# AVR32DA48 device description
Architecture: AVR8X; Family: AVR DA
Registers are 8-bit, read-write, reset 0x0 unless marked. A register's access mark holds for its fields unless they carry their own. Offsets are from the block's base; [hi:lo] are bit positions; {n}, {i} and the like mark numbered series; 'fields as' and 'values as' point back to an identical list; <NAME> marks a mode.

## SPI — Serial Peripheral Interface
Instances: SPI0 0x0940, SPI1 0x0960
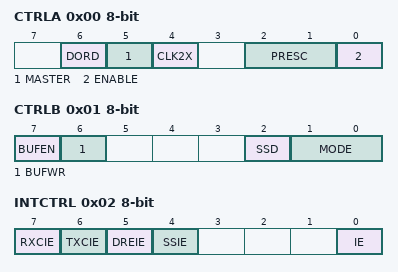
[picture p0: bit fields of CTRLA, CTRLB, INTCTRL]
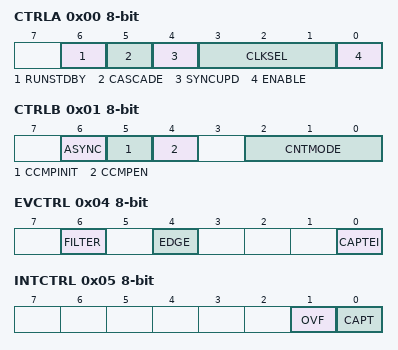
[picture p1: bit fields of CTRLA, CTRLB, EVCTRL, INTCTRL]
0x00 CTRLA — Control A
  [6] DORD — Data Order Setting
  [5] MASTER — Master Operation Enable
  [4] CLK2X — Enable Double Speed
  [2:1] PRESC — Prescaler
    0=DIV4 (System Clock / 4); 1=DIV16 (System Clock / 16); 2=DIV64 (System Clock / 64); 3=DIV128 (System Clock / 128)
  [0] ENABLE — Enable Module
0x01 CTRLB — Control B
  [7] BUFEN — Buffer Mode Enable
  [6] BUFWR — Buffer Mode Wait for Receive
  [2] SSD — Slave Select Disable
  [1:0] MODE — SPI Mode
    {v}=SPI Mode {v} (v=0..3)
0x02 INTCTRL — Interrupt Control
  [7] RXCIE — Receive Complete Interrupt Enable
  [6] TXCIE — Transfer Complete Interrupt Enable
  [5] DREIE — Data Register Empty Interrupt Enable
  [4] SSIE — Slave Select Trigger Interrupt Enable
  [0] IE — Interrupt Enable
0x03 INTFLAGS — Interrupt Flags
  [7] RXCIF <BUFFERED> — Receive Complete Interrupt Flag
  [6] TXCIF <BUFFERED> — Transfer Complete Interrupt Flag
  [5] DREIF <BUFFERED> — Data Register Empty Interrupt Flag
  [4] SSIF <BUFFERED> — Slave Select Trigger Interrupt Flag
  [0] BUFOVF <BUFFERED> — Buffer Overflow
  [7] IF <DEFAULT> — Interrupt Flag
  [6] WRCOL <DEFAULT> — Write Collision
0x04 DATA reset not defined

## SYSCFG — System Configuration Registers
Instances: SYSCFG 0x0F00
0x01 REVID reset not defined — Revision ID
0x18 OCDMCTRL reset not defined — OCD Message Control
0x19 OCDMSTATUS — OCD Message Status
  [0] OCDMR — OCD Message Read

## TCB — 16-bit Timer Type B
Instances: TCB{n} {0xB00+0x10*n} (n=0..3)
0x00 CTRLA — Control A
  [6] RUNSTDBY — Run Standby
  [5] CASCADE — Cascade two timers
  [4] SYNCUPD — Synchronize Update
  [3:1] CLKSEL — Clock Select
    0=DIV1 (CLK_PER); 1=DIV2 (CLK_PER/2); 2=TCA0 (Use CLK_TCA from TCA0); 7=EVENT (Count on event edge); 3=TCA1 (Use CLK_TCA from TCA1)
  [0] ENABLE
0x01 CTRLB — Control Register B
  [6] ASYNC — Asynchronous Enable
  [5] CCMPINIT — Pin Initial State
  [4] CCMPEN — Pin Output Enable
  [2:0] CNTMODE — Timer Mode
    0=INT (Periodic Interrupt); 1=TIMEOUT (Periodic Timeout); 2=CAPT (Input Capture Event); 3=FRQ (Input Capture Frequency measurement); 4=PW (Input Capture Pulse-Width measurement); 5=FRQPW (Input Capture Frequency and Pulse-Width measurement); 6=SINGLE (Single Shot); 7=PWM8 (8-bit PWM)
0x04 EVCTRL — Event Control
  [6] FILTER — Input Capture Noise Cancellation Filter
  [4] EDGE — Event Edge
  [0] CAPTEI — Event Input Enable
0x05 INTCTRL — Interrupt Control
  [1] OVF — Overflow
  [0] CAPT — Capture or Timeout
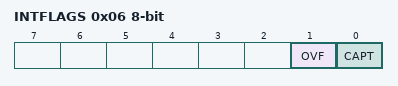
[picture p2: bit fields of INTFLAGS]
0x06 INTFLAGS — Interrupt Flags
  [1] OVF — Overflow
  [0] CAPT — Capture or Timeout
0x07 STATUS ro
  [0] RUN
0x08 DBGCTRL — Debug Control
  [0] DBGRUN — Debug Run
0x09 TEMP reset not defined — Temporary Value
0x0A CNT 16-bit — Count
0x0C CCMP 16-bit reset not defined — Compare or Capture

## TWI — Two-Wire Interface
Instances: TWI0 0x0900, TWI1 0x0920
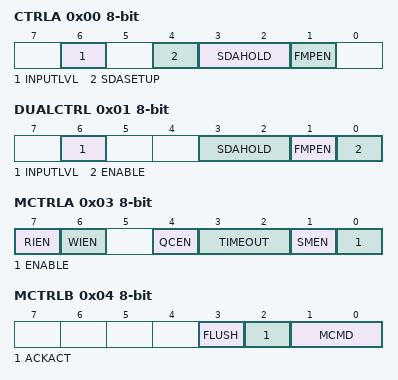
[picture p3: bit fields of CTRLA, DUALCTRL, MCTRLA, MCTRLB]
0x00 CTRLA — Control A
  [6] INPUTLVL <DEFAULT> — Input Voltage Transition Level
    0=I2C (I2C input voltage transition level); 1=SMBUS (SMBus 3.0 input voltage transition level)
  [4] SDASETUP <DEFAULT> — SDA Setup Time
    0=4CYC (SDA setup time is 4 clock cycles); 1=8CYC (SDA setup time is 8 clock cycles)
  [3:2] SDAHOLD <DEFAULT> — SDA Hold Time
    0=OFF (SDA hold time off); 1=50NS (Typical 50ns hold time); 2=300NS (Typical 300ns hold time); 3=500NS (Typical 500ns hold time)
  [1] FMPEN <DEFAULT> — FM Plus Enable
0x01 DUALCTRL — Dual Control
  [6] INPUTLVL <DEFAULT> — Input Voltage Transition Level
    values as CTRLA.INPUTLVL<DEFAULT>
  [3:2] SDAHOLD <DEFAULT> — SDA Hold Time
    values as CTRLA.SDAHOLD<DEFAULT>
  [1] FMPEN <DEFAULT> — FM Plus Enable
  [0] ENABLE <DEFAULT> — Dual Control Enable
0x02 DBGCTRL — Debug Control Register
  [0] DBGRUN <DEFAULT> — Debug Run
0x03 MCTRLA — Master Control A
  [7] RIEN — Read Interrupt Enable
  [6] WIEN — Write Interrupt Enable
  [4] QCEN — Quick Command Enable
  [3:2] TIMEOUT — Inactive Bus Timeout
    0=DISABLED (Bus Timeout Disabled); 1=50US (50 Microseconds); 2=100US (100 Microseconds); 3=200US (200 Microseconds)
  [1] SMEN — Smart Mode Enable
  [0] ENABLE — Enable TWI Master
0x04 MCTRLB — Master Control B
  [3] FLUSH
  [2] ACKACT — Acknowledge Action
    0=ACK (Send ACK); 1=NACK (Send NACK)
  [1:0] MCMD — Command
    0=NOACT (No Action); 1=REPSTART (Issue Repeated Start Condition); 2=RECVTRANS (Receive or Transmit Data, depending on DIR); 3=STOP (Issue Stop Condition)
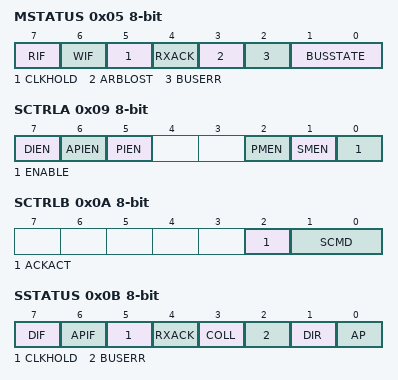
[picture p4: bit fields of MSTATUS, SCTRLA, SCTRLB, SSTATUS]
0x05 MSTATUS — Master Status
  [7] RIF — Read Interrupt Flag
  [6] WIF — Write Interrupt Flag
  [5] CLKHOLD — Clock Hold
  [4] RXACK ro — Received Acknowledge
  [3] ARBLOST — Arbitration Lost
  [2] BUSERR — Bus Error
  [1:0] BUSSTATE
    0=UNKNOWN (Unknown Bus State); 1=IDLE (Bus is Idle); 2=OWNER (This Module Controls The Bus); 3=BUSY (The Bus is Busy)
0x06 MBAUD reset not defined — Master Baud Rate Control
0x07 MADDR reset not defined — Master Address
0x08 MDATA reset not defined — Master Data
0x09 SCTRLA — Slave Control A
  [7] DIEN — Data Interrupt Enable
  [6] APIEN — Address/Stop Interrupt Enable
  [5] PIEN — Stop Interrupt Enable
  [2] PMEN — Promiscuous Mode Enable
  [1] SMEN — Smart Mode Enable
  [0] ENABLE — Enable TWI Slave
0x0A SCTRLB — Slave Control B
  [2] ACKACT — Acknowledge Action
    0=ACK (Send ACK); 1=NACK (Send NACK)
  [1:0] SCMD — Command
    0=NOACT (No Action); 2=COMPTRANS (Used To Complete a Transaction); 3=RESPONSE (Used in Response to Address/Data Interrupt)
0x0B SSTATUS — Slave Status
  [7] DIF — Data Interrupt Flag
  [6] APIF — Address/Stop Interrupt Flag
  [5] CLKHOLD ro — Clock Hold
  [4] RXACK ro — Received Acknowledge
  [3] COLL — Collision
  [2] BUSERR — Bus Error
  [1] DIR ro — Read/Write Direction
  [0] AP ro — Slave Address or Stop
    0=STOP (Stop condition generated APIF); 1=ADR (Address detection generated APIF)
0x0C SADDR reset not defined — Slave Address
0x0D SDATA reset not defined — Slave Data
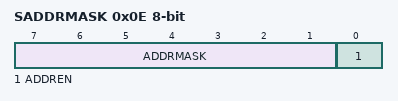
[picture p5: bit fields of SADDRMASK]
0x0E SADDRMASK reset not defined — Slave Address Mask
  [7:1] ADDRMASK — Address Mask
  [0] ADDREN — Address Enable
